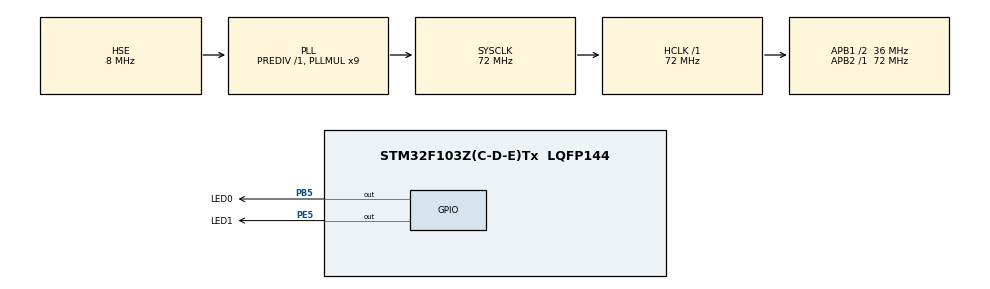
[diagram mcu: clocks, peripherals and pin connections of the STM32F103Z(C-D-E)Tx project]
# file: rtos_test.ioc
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Mcu.Family=STM32F1
Mcu.Name=STM32F103Z(C-D-E)Tx
Mcu.Package=LQFP144
NVIC.PriorityGroup=NVIC_PRIORITYGROUP_4
OSC_IN.Mode=HSE-External-Oscillator
OSC_IN.Signal=RCC_OSC_IN
OSC_OUT.Mode=HSE-External-Oscillator
OSC_OUT.Signal=RCC_OSC_OUT
PA13.Mode=Serial_Wire
PA13.Signal=SYS_JTMS-SWDIO
PA14.Mode=Serial_Wire
PA14.Signal=SYS_JTCK-SWCLK
PB5.GPIO_Label=LED0
PB5.PinState=GPIO_PIN_SET
PB5.Signal=GPIO_Output
PC14-OSC32_IN.Mode=LSE-External-Oscillator
PC14-OSC32_IN.Signal=RCC_OSC32_IN
PC15-OSC32_OUT.Mode=LSE-External-Oscillator
PC15-OSC32_OUT.Signal=RCC_OSC32_OUT
PE5.GPIO_Label=LED1
PE5.PinState=GPIO_PIN_SET
PE5.Signal=GPIO_Output
ProjectManager.HeapSize=0x200
ProjectManager.StackSize=0x400
ProjectManager.TargetToolchain=Makefile
RCC.AHBFreq_Value=72000000
RCC.APB1CLKDivider=RCC_HCLK_DIV2
RCC.APB1Freq_Value=36000000
RCC.APB1TimFreq_Value=72000000
RCC.APB2Freq_Value=72000000
RCC.APB2TimFreq_Value=72000000
RCC.HCLKFreq_Value=72000000
RCC.PLLMUL=RCC_PLL_MUL9
RCC.PLLSourceVirtual=RCC_PLLSOURCE_HSE
RCC.SYSCLKFreq_VALUE=72000000
RCC.SYSCLKSource=RCC_SYSCLKSOURCE_PLLCLK
RCC.USBFreq_Value=72000000
RealThread.RT-Thread.3.1.3.RTAaThreadCcRTOSJjkernel=true
VP_RealThread.RT-Thread_VS_RTOSJjRTAaThread_3.1.3.Mode=RTOSJjRTAaThread
board=custom

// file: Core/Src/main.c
/* USER CODE BEGIN Header */
/**
  ******************************************************************************
  * @file           : main.c
  * @brief          : Main program body
  ******************************************************************************
  * @attention
  *
  * <h2><center>&copy; Copyright (c) 2021 STMicroelectronics.
  * All rights reserved.</center></h2>
  *
  * This software component is licensed by ST under Ultimate Liberty license
  * SLA0044, the "License"; You may not use this file except in compliance with
  * the License. You may obtain a copy of the License at:
  *                             www.st.com/SLA0044
  *
  ******************************************************************************
  */
/* USER CODE END Header */
#include "main.h"
#include "gpio.h"

/* USER CODE BEGIN Includes */
#include "rtthread.h"
/* USER CODE END Includes */

/* USER CODE BEGIN PTD */
/*创建静态内存栈*/
static struct rt_thread led0_thread;
static rt_uint8_t led0_thread_stack[512];
/* USER CODE END PTD */

void SystemClock_Config(void);

/* USER CODE BEGIN 0 */
/*线程入口*/
void led0_thread_entry(void* parameter)
{
  while (1)
  {
    HAL_GPIO_WritePin(LED1_GPIO_Port, LED1_Pin, GPIO_PIN_SET);
    rt_thread_mdelay(500);
    HAL_GPIO_WritePin(LED1_GPIO_Port, LED1_Pin, GPIO_PIN_RESET);
    rt_thread_mdelay(500);
  }
}

int led0_thread_init(void)
{
  rt_thread_t ptr;
  rt_err_t result;
  result = rt_thread_init(&led0_thread,
                          "led0_thread",
                          led0_thread_entry,RT_NULL,
                          &led0_thread_stack[0],sizeof(led0_thread_stack),
                          RT_THREAD_PRIORITY_MAX - 3, 20);
  if (result == RT_EOK) rt_thread_startup(&led0_thread);
  return 0;
}

/* USER CODE END 0 */

int main(void)
{

  /* MCU Configuration--------------------------------------------------------*/

  /* Reset of all peripherals, Initializes the Flash interface and the Systick. */
  HAL_Init();

  /* Configure the system clock */
  //ystemClock_Config();

  /* Initialize all configured peripherals */
  MX_GPIO_Init();

  /* Infinite loop */
  /* USER CODE BEGIN WHILE */
  led0_thread_init();
  while (1)
  {
    HAL_GPIO_TogglePin(LED0_GPIO_Port, LED0_Pin);
    rt_thread_mdelay(333);
    //比如我现在修改了这个文件
    //修改
    /* USER CODE END WHILE */

  }
}

void SystemClock_Config(void)
{
  RCC_OscInitTypeDef RCC_OscInitStruct = {0};
  RCC_ClkInitTypeDef RCC_ClkInitStruct = {0};

  /** Initializes the RCC Oscillators according to the specified parameters
  * in the RCC_OscInitTypeDef structure.
  */
  RCC_OscInitStruct.OscillatorType = RCC_OSCILLATORTYPE_HSE;
  RCC_OscInitStruct.HSEState = RCC_HSE_ON;
  RCC_OscInitStruct.HSEPredivValue = RCC_HSE_PREDIV_DIV1;
  RCC_OscInitStruct.HSIState = RCC_HSI_ON;
  RCC_OscInitStruct.PLL.PLLState = RCC_PLL_ON;
  RCC_OscInitStruct.PLL.PLLSource = RCC_PLLSOURCE_HSE;
  RCC_OscInitStruct.PLL.PLLMUL = RCC_PLL_MUL9;
  if (HAL_RCC_OscConfig(&RCC_OscInitStruct) != HAL_OK)
  {
    Error_Handler();
  }
  /** Initializes the CPU, AHB and APB buses clocks
  */
  RCC_ClkInitStruct.ClockType = RCC_CLOCKTYPE_HCLK|RCC_CLOCKTYPE_SYSCLK
                              |RCC_CLOCKTYPE_PCLK1|RCC_CLOCKTYPE_PCLK2;
  RCC_ClkInitStruct.SYSCLKSource = RCC_SYSCLKSOURCE_PLLCLK;
  RCC_ClkInitStruct.AHBCLKDivider = RCC_SYSCLK_DIV1;
  RCC_ClkInitStruct.APB1CLKDivider = RCC_HCLK_DIV2;
  RCC_ClkInitStruct.APB2CLKDivider = RCC_HCLK_DIV1;

  if (HAL_RCC_ClockConfig(&RCC_ClkInitStruct, FLASH_LATENCY_2) != HAL_OK)
  {
    Error_Handler();
  }
}

void Error_Handler(void)
{
}

/************************ (C) COPYRIGHT STMicroelectronics *****END OF FILE****/
